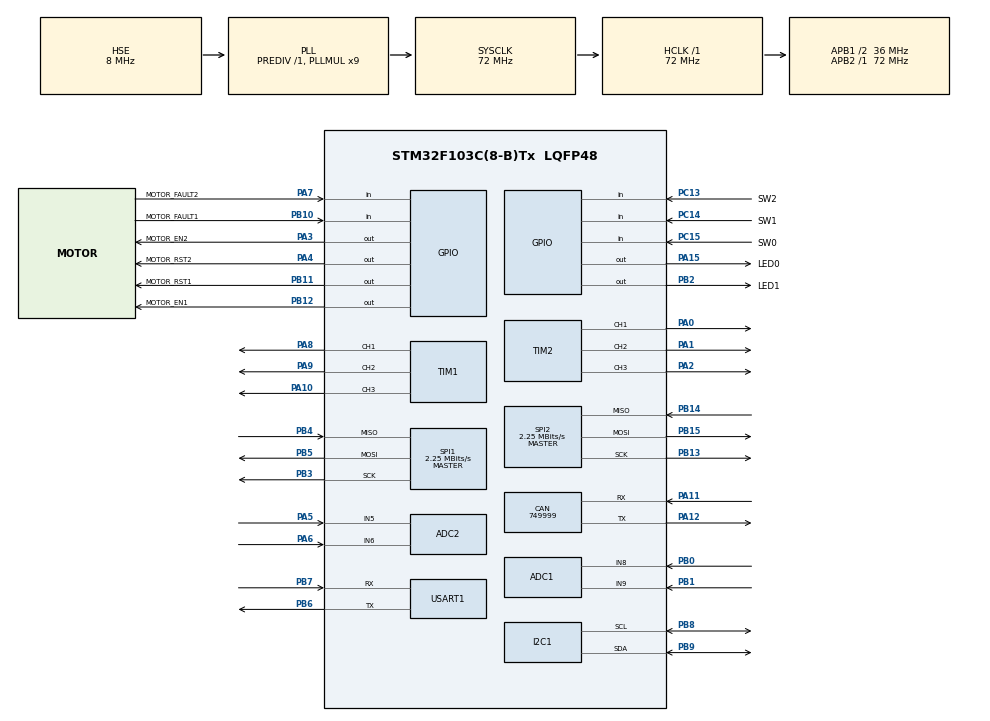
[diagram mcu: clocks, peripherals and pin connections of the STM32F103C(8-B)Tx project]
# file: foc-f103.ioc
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ADC1.Channel-4\#ChannelRegularConversion=ADC_CHANNEL_8
ADC1.NbrOfConversionFlag=1
ADC1.Rank-4\#ChannelRegularConversion=1
ADC1.SamplingTime-4\#ChannelRegularConversion=ADC_SAMPLETIME_1CYCLE_5
ADC1.master=1
ADC2.Channel-3\#ChannelRegularConversion=ADC_CHANNEL_5
ADC2.NbrOfConversionFlag=1
ADC2.Rank-3\#ChannelRegularConversion=1
ADC2.SamplingTime-3\#ChannelRegularConversion=ADC_SAMPLETIME_1CYCLE_5
CAN.CalculateBaudRate=749999
CAN.CalculateTimeBit=1333
CAN.CalculateTimeQuantum=444.44444444444446
Mcu.Family=STM32F1
Mcu.Name=STM32F103C(8-B)Tx
Mcu.Package=LQFP48
NVIC.PriorityGroup=NVIC_PRIORITYGROUP_4
PA0-WKUP.Signal=S_TIM2_CH1_ETR
PA1.Signal=S_TIM2_CH2
PA10.Signal=S_TIM1_CH3
PA11.Mode=CAN_Activate
PA11.Signal=CAN_RX
PA12.Mode=CAN_Activate
PA12.Signal=CAN_TX
PA13.Mode=Serial_Wire
PA13.Signal=SYS_JTMS-SWDIO
PA14.Mode=Serial_Wire
PA14.Signal=SYS_JTCK-SWCLK
PA15.GPIO_Label=LED0
PA15.Signal=GPIO_Output
PA2.Signal=S_TIM2_CH3
PA3.GPIO_Label=MOTOR_EN2
PA3.Signal=GPIO_Output
PA4.GPIO_Label=MOTOR_RST2
PA4.Signal=GPIO_Output
PA5.Signal=ADCx_IN5
PA6.Signal=ADCx_IN6
PA7.GPIO_Label=MOTOR_FAULT2
PA7.Signal=GPIO_Input
PA8.Signal=S_TIM1_CH1
PA9.Signal=S_TIM1_CH2
PB0.Signal=ADCx_IN8
PB1.Signal=ADCx_IN9
PB10.GPIO_Label=MOTOR_FAULT1
PB10.Signal=GPIO_Input
PB11.GPIO_Label=MOTOR_RST1
PB11.Signal=GPIO_Output
PB12.GPIO_Label=MOTOR_EN1
PB12.Signal=GPIO_Output
PB13.Mode=Full_Duplex_Master
PB13.Signal=SPI2_SCK
PB14.Mode=Full_Duplex_Master
PB14.Signal=SPI2_MISO
PB15.Mode=Full_Duplex_Master
PB15.Signal=SPI2_MOSI
PB2.GPIO_Label=LED1
PB2.Signal=GPIO_Output
PB3.Mode=Full_Duplex_Master
PB3.Signal=SPI1_SCK
PB4.Mode=Full_Duplex_Master
PB4.Signal=SPI1_MISO
PB5.Mode=Full_Duplex_Master
PB5.Signal=SPI1_MOSI
PB6.Mode=Asynchronous
PB6.Signal=USART1_TX
PB7.Mode=Asynchronous
PB7.Signal=USART1_RX
PB8.Mode=I2C
PB8.Signal=I2C1_SCL
PB9.Mode=I2C
PB9.Signal=I2C1_SDA
PC13-TAMPER-RTC.GPIO_Label=SW2
PC13-TAMPER-RTC.Signal=GPIO_Input
PC14-OSC32_IN.GPIO_Label=SW1
PC14-OSC32_IN.Signal=GPIO_Input
PC15-OSC32_OUT.GPIO_Label=SW0
PC15-OSC32_OUT.Signal=GPIO_Input
PD0-OSC_IN.Mode=HSE-External-Oscillator
PD0-OSC_IN.Signal=RCC_OSC_IN
PD1-OSC_OUT.Mode=HSE-External-Oscillator
PD1-OSC_OUT.Signal=RCC_OSC_OUT
ProjectManager.HeapSize=0x200
ProjectManager.StackSize=0x400
ProjectManager.TargetToolchain=Makefile
RCC.ADCPresc=RCC_ADCPCLK2_DIV6
RCC.AHBFreq_Value=72000000
RCC.APB1CLKDivider=RCC_HCLK_DIV2
RCC.APB1Freq_Value=36000000
RCC.APB1TimFreq_Value=72000000
RCC.APB2Freq_Value=72000000
RCC.APB2TimFreq_Value=72000000
RCC.HCLKFreq_Value=72000000
RCC.PLLMUL=RCC_PLL_MUL9
RCC.PLLSourceVirtual=RCC_PLLSOURCE_HSE
RCC.SYSCLKFreq_VALUE=72000000
RCC.SYSCLKSource=RCC_SYSCLKSOURCE_PLLCLK
RCC.USBFreq_Value=72000000
SH.ADCx_IN5.0=ADC2_IN5,IN5
SH.ADCx_IN6.0=ADC2_IN6,IN6
SH.ADCx_IN8.0=ADC1_IN8,IN8
SH.ADCx_IN9.0=ADC1_IN9,IN9
SH.S_TIM1_CH1.0=TIM1_CH1,PWM Generation1 CH1
SH.S_TIM1_CH2.0=TIM1_CH2,Output Compare2 CH2
SH.S_TIM1_CH3.0=TIM1_CH3,Output Compare3 CH3
SH.S_TIM2_CH1_ETR.0=TIM2_CH1,PWM Generation1 CH1
SH.S_TIM2_CH2.0=TIM2_CH2,PWM Generation2 CH2
SH.S_TIM2_CH3.0=TIM2_CH3,PWM Generation3 CH3
SPI1.BaudRatePrescaler=SPI_BAUDRATEPRESCALER_32
SPI1.CLKPhase=SPI_PHASE_2EDGE
SPI1.CalculateBaudRate=2.25 MBits/s
SPI1.DataSize=SPI_DATASIZE_16BIT
SPI1.Direction=SPI_DIRECTION_2LINES
SPI1.Mode=SPI_MODE_MASTER
SPI1.VirtualType=VM_MASTER
SPI2.BaudRatePrescaler=SPI_BAUDRATEPRESCALER_16
SPI2.CLKPhase=SPI_PHASE_2EDGE
SPI2.CalculateBaudRate=2.25 MBits/s
SPI2.DataSize=SPI_DATASIZE_16BIT
SPI2.Direction=SPI_DIRECTION_2LINES
SPI2.Mode=SPI_MODE_MASTER
SPI2.VirtualType=VM_MASTER
TIM1.Channel-Output\ Compare2\ CH2=TIM_CHANNEL_2
TIM1.Channel-Output\ Compare3\ CH3=TIM_CHANNEL_3
TIM1.Channel-PWM\ Generation1\ CH1=TIM_CHANNEL_1
TIM2.Channel-PWM\ Generation1\ CH1=TIM_CHANNEL_1
TIM2.Channel-PWM\ Generation2\ CH2=TIM_CHANNEL_2
TIM2.Channel-PWM\ Generation3\ CH3=TIM_CHANNEL_3
USART1.VirtualMode=VM_ASYNC
board=custom

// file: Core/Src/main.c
/* USER CODE BEGIN Header */
/**
  ******************************************************************************
  * @file           : main.c
  * @brief          : Main program body
  ******************************************************************************
  * @attention
  *
  * Copyright (c) 2024 STMicroelectronics.
  * All rights reserved.
  *
  * This software is licensed under terms that can be found in the LICENSE file
  * in the root directory of this software component.
  * If no LICENSE file comes with this software, it is provided AS-IS.
  *
  ******************************************************************************
  */
/* USER CODE END Header */
#include "main.h"
#include "adc.h"
#include "can.h"
#include "i2c.h"
#include "spi.h"
#include "tim.h"
#include "usart.h"
#include "gpio.h"

/* USER CODE BEGIN Includes */
#include <FreeRTOS.h>
#include <task.h>
#include <UserTask.h>
/* USER CODE END Includes */

void SystemClock_Config(void);

int main(void)
{

  /* MCU Configuration--------------------------------------------------------*/

  /* Reset of all peripherals, Initializes the Flash interface and the Systick. */
  HAL_Init();

  /* Configure the system clock */
  SystemClock_Config();

  /* Initialize all configured peripherals */
  MX_GPIO_Init();
  MX_CAN_Init();
  MX_SPI1_Init();
  MX_TIM1_Init();
  MX_USART1_UART_Init();
  MX_ADC1_Init();
  MX_ADC2_Init();
  MX_SPI2_Init();
  MX_I2C1_Init();
  MX_TIM2_Init();
  /* USER CODE BEGIN 2 */
  createUserTasks();
  vTaskStartScheduler();
  /* USER CODE END 2 */

  /* Infinite loop */
  /* USER CODE BEGIN WHILE */
  while (1)
  {
    assert_param(0); // Should never get here
    /* USER CODE END WHILE */

  }
}

void SystemClock_Config(void)
{
  RCC_OscInitTypeDef RCC_OscInitStruct = {0};
  RCC_ClkInitTypeDef RCC_ClkInitStruct = {0};
  RCC_PeriphCLKInitTypeDef PeriphClkInit = {0};

  /** Initializes the RCC Oscillators according to the specified parameters
  * in the RCC_OscInitTypeDef structure.
  */
  RCC_OscInitStruct.OscillatorType = RCC_OSCILLATORTYPE_HSE;
  RCC_OscInitStruct.HSEState = RCC_HSE_ON;
  RCC_OscInitStruct.HSEPredivValue = RCC_HSE_PREDIV_DIV1;
  RCC_OscInitStruct.HSIState = RCC_HSI_ON;
  RCC_OscInitStruct.PLL.PLLState = RCC_PLL_ON;
  RCC_OscInitStruct.PLL.PLLSource = RCC_PLLSOURCE_HSE;
  RCC_OscInitStruct.PLL.PLLMUL = RCC_PLL_MUL9;
  if (HAL_RCC_OscConfig(&RCC_OscInitStruct) != HAL_OK)
  {
    Error_Handler();
  }

  /** Initializes the CPU, AHB and APB buses clocks
  */
  RCC_ClkInitStruct.ClockType = RCC_CLOCKTYPE_HCLK|RCC_CLOCKTYPE_SYSCLK
                              |RCC_CLOCKTYPE_PCLK1|RCC_CLOCKTYPE_PCLK2;
  RCC_ClkInitStruct.SYSCLKSource = RCC_SYSCLKSOURCE_PLLCLK;
  RCC_ClkInitStruct.AHBCLKDivider = RCC_SYSCLK_DIV1;
  RCC_ClkInitStruct.APB1CLKDivider = RCC_HCLK_DIV2;
  RCC_ClkInitStruct.APB2CLKDivider = RCC_HCLK_DIV1;

  if (HAL_RCC_ClockConfig(&RCC_ClkInitStruct, FLASH_LATENCY_2) != HAL_OK)
  {
    Error_Handler();
  }
  PeriphClkInit.PeriphClockSelection = RCC_PERIPHCLK_ADC;
  PeriphClkInit.AdcClockSelection = RCC_ADCPCLK2_DIV6;
  if (HAL_RCCEx_PeriphCLKConfig(&PeriphClkInit) != HAL_OK)
  {
    Error_Handler();
  }
}

void Error_Handler(void)
{
  __disable_irq();
  while (1)
  {
  }
}
